# max32690 register map
Vendor: Maxim-Integrated; Series: ARMCM4; File version: 1.0
CPU: CM4 r2p1, little endian, MPU, FPU, 3 interrupt priority bits
Registers are 32-bit, read-write, reset 0x0 unless marked. A register's access mark holds for its fields unless they carry their own. Offsets are from the block's base; [hi:lo] are bit positions; {n}, {i} and the like mark numbered series; 'fields as' and 'values as' point back to an identical list.

## CAN0 — Controller Area Network Registers
Base 0x40064000
Same registers: CAN2 ?, CAN1 0x40065000
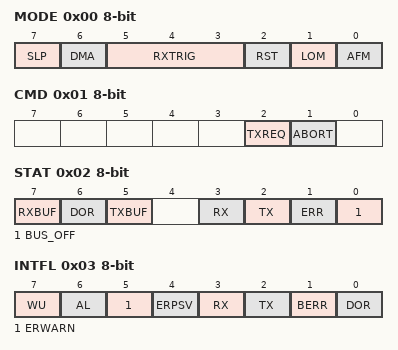
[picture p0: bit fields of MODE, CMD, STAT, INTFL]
0x00 MODE 8-bit
  [7] SLP — Sleep mode.
    1=Enter sleep mode; 0=Leave sleep mode
  [6] DMA — Enable DMA mode.
  [5:3] RXTRIG — Receive FIFO trigger in 32bit word.
    0=1W (1 word); 1=4W (4 word); 2=8W (8 word); 3=16W (16 word); 4=32W (32 word); 5=64W (64 word)
  [2] RST — Reset Mode.
  [1] LOM — Listen Only Mode.
  [0] AFM — Hardware acceptance filter scheme.
0x01 CMD 8-bit — Command Register.
  [2] TXREQ — Transmit Request.
  [1] ABORT — Abort Transmission
0x02 STAT 8-bit ro — Status Register.
  [7] RXBUF — Receive Buffer Status.
  [6] DOR — Data Overrun Status.
  [5] TXBUF — Transmit Buffer Status.
  [3] RX — Receive Status.
  [2] TX — Transmit Status.
  [1] ERR — Error Status.
  [0] BUS_OFF — Bus off Status.
0x03 INTFL 8-bit — Interrupt Status Register.
  [7] WU — Wake-up Interrupt.
  [6] AL — Arbitration Lost Interrupt.
  [5] ERWARN — Error Warning Interrupt.
  [4] ERPSV — Error Passive Interrupt.
  [3] RX — Receive Interrupt.
  [2] TX — Transmission Interrupt.
  [1] BERR — Bus Error Interrupt.
  [0] DOR — Data Overrun Interrupt.
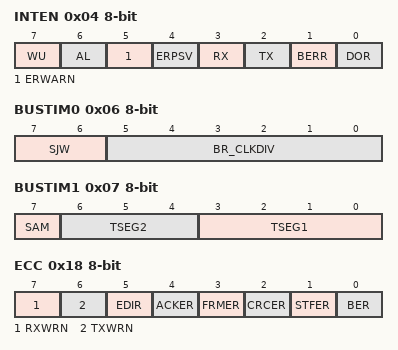
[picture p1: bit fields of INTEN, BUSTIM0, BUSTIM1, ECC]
0x04 INTEN 8-bit — Interrupt Enable Register.
  [7] WU — Wakeup interrupt.
  [6] AL — Arbitration Lost Interrupt.
  [5] ERWARN — Error Warning Interrupt.
  [4] ERPSV — Error Passive Interrupt.
  [3] RX — Receive Interrupt.
  [2] TX — Transmit Interrupt.
  [1] BERR — Bus Error Interrupt.
  [0] DOR — Data Overrun Interrupt.
0x05 RMC 8-bit — Receive Message Counter Register.
  [4:0] NUM_MSGS — Number of stored message frames.
0x06 BUSTIM0 8-bit — Bus Timing Register 0.
  [7:6] SJW — Synchronization Jump Width.
  [5:0] BR_CLKDIV — Baud Rate Prescaler.
0x07 BUSTIM1 8-bit — Bus Timing Register 1.
  [7] SAM — Number of bus level samples.
  [6:4] TSEG2 — Number of clock cycles per Time Segment 2
  [3:0] TSEG1 — Number of clock cycles per Time Segment 1
0x08 TXFIFO32 — Transmit FIFO Register.
  [31:0] DATA — Write to put into TX FIFO.
{0x8+2i} TXFIFO16[{i}] (i=0..1) 16-bit — Transmit FIFO Register.
  [15:0] DATA — Write to put into TX FIFO.
{0x8+i} TXFIFO8[{i}] (i=0..3) 8-bit — Transmit FIFO Register.
  [7:0] DATA — Write to put into TX FIFO.
0x0C RXFIFO32 ro — Receive FIFO Register.
  [31:0] DATA — Read from RX FIFO.
{0xC+2i} RXFIFO16[{i}] (i=0..1) 16-bit ro — Receive FIFO Register.
  [15:0] DATA — Read from RX FIFO.
{0xC+i} RXFIFO8[{i}] (i=0..3) 8-bit ro — Receive FIFO Register.
  [7:0] DATA — Read from RX FIFO.
0x10 ACR32 — Acceptance Code Register.
  [31:0] ACR — Acceptance Code.
{0x10+2i} ACR16[{i}] (i=0..1) 16-bit — Acceptance Code Register.
  [15:0] ACR — Acceptance Code.
{0x10+i} ACR8[{i}] (i=0..3) 8-bit — Acceptance Code Register.
  [7:0] ACR — Acceptance Code.
0x14 AMR32 — Acceptance Mask Register.
  [31:0] AMR — Acceptance Mask.
{0x14+2i} AMR16[{i}] (i=0..1) 16-bit — Acceptance Mask Register.
  [15:0] AMR — Acceptance Mask.
{0x14+i} AMR8[{i}] (i=0..3) 8-bit — Acceptance Mask Register.
  [7:0] AMR — Acceptance Mask.
0x18 ECC 8-bit ro — Error Code Capture Register.
  [7] RXWRN — Set when RXERR counter is greater than or equal to 96.
  [6] TXWRN — Set when TXERR counter is greater than or equal to 96.
  [5] EDIR — Direction of transfer while error occurred.
    0=TX (Transmission); 1=RX (Reception)
  [4] ACKER — ACK Error Occurred.
  [3] FRMER — Form Error Occurred.
  [2] CRCER — CRC Error Occurred.
  [1] STFER — Stuff Error Occurred.
  [0] BER — Bit Error Occurred.
0x19 RXERR 8-bit — Receive Error Counter.
0x1A TXERR 8-bit — Invalidate All Registers.
  [7:0] TXERR — Transmit Error Counter.
0x1B ALC 8-bit ro — Arbitration Lost Code Capture Register.
  [4:0] ALC — Arbitration Lost Capture.
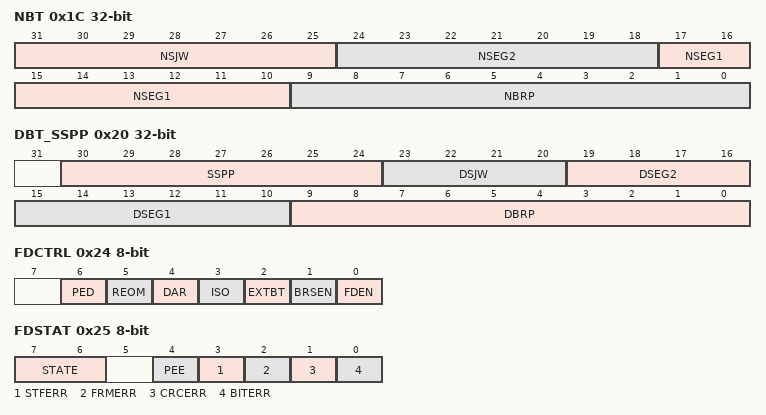
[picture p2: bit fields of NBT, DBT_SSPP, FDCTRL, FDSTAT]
0x1C NBT — Nominal Bit Timing Register.
  [31:25] NSJW — Synchronization Jump Width in Arbitration Phase.
  [24:18] NSEG2 — The time segment after the sample point in Abritration Phase.
  [17:10] NSEG1 — The time segment before the sample point in Abritration Phase.
  [9:0] NBRP — Baudrate Prescaler Used in Arbitration Phase.
0x20 DBT_SSPP — Data Bit Timing Register.
  [30:24] SSPP — Position of the secondary sample point.
  [23:20] DSJW — Synchronization Jump Width in Data Phase
  [19:16] DSEG2 — The time segment before the sample point in Data Phase.
  [15:10] DSEG1 — The time segment before the sample point in Data Phase.
  [9:0] DBRP — Baudrate Prescaler in Data Phase.
0x24 FDCTRL 8-bit — FD Control Register.
  [6] PED — Protocol Exception Disable.
  [5] REOM — Restricted Operation Mode.
  [4] DAR — Disable Auto Retransmission
    0=EN (Automatic retransmission enabled.); 1=DIS (Automatic retransmission disabled.)
  [3] ISO — ISO CAN FD Format Selection.
    0=BOSCH (Frame format according to Bosch CAN FD specification.); 1=ISO (Frame format according to ISO 11898 1, 2015.)
  [2] EXTBT — This bit configure the Bit Time prescaler in Arbitration phase.
    0=BT (Use contents of BT register to configure bit time in arbitration phase.); 1=NBT (Use contents of NBT register to configure bit time in arbitration phase.)
  [1] BRSEN — This bit indicates whether the bit rate is switched in Data phase.
    0=NOSW (Bit rate is not switced inside of CAN FD frame.); 1=SW (Bit rate is switched from nominal bit rate of the arbitration phase to alternate bit rate of data phase.)
  [0] FDEN — FD Frame format/ Extended data length. This bit indicates CAN FD frame format.
    1=fd (CAN FD Frame Format); 0=Classic CAN Frame Format
0x25 FDSTAT 8-bit ro — Invalidate All Registers.
  [7:6] STATE — Operation state.
    0=INT (Waiting for 11 recessive bit after reset or bus off); 1=IDLE (Waiting for Start of Frame.); 2=RX (Node operating as Receiver.); 3=TX (Node operating as Transmitter.)
  [4] PEE — Protocol Exception Event indicator. Indicates that core detects recessive state on res position and enter to Bus integration state.
  [3] STFERR — Stuff Error Indicator. This bit indicates stuff error occurred in Data phase in CAN FD frame with the BRS bit set
  [2] FRMERR — Form Error indicator. This bit indicates, that a fixed form bit field contains at least one illegal bit in Data phase of CAN FD frame with the BRS bit set
  [1] CRCERR — Cyclic Redundancy Check Error indicator. This indicates that calculated CRC is different from received in CAN FD frame
  [0] BITERR — Bit Error Indicator. When this bit is set the inconsistency occurs between the transmitted and the received bit in CAN FD frame.
0x26 DPERR 8-bit ro — Data Phase Error Counter Register.
  [7:0] DPERR — Data Phase Error Counter.
0x27 APERR 8-bit ro — Arbitration Phase Error Counter Register.
  [7:0] APERR — Arbitration Error Counter.
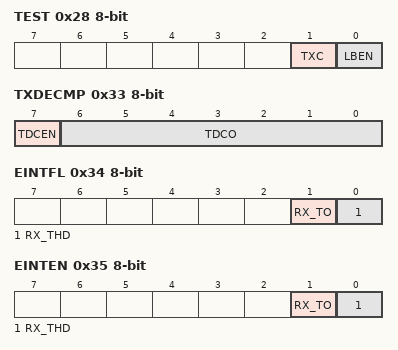
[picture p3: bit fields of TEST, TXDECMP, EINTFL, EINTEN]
0x28 TEST 8-bit — Invalidate All Registers.
  [1] TXC — Transmitted frame.
  [0] LBEN — Loopback mode.
0x29 WUPCLKDIV 8-bit — Wake-up timer prescaler.
  [7:0] WUPDIV
0x2A WUPFT 16-bit — Wake up Filter Time Register.
  [15:0] WUPFT — Wake-up pattern filter time.
0x2C WUPET — Wake-up Expire Time Register.
  [19:0] WUPET — Wake up patter expire time.
0x30 RXDCNT 16-bit — RX FIFO Data Counter Register.
  [15:0] RXDCNT — RX FIFO data counter.
0x32 TXSCNT 8-bit — TX FIFO Space Counter.
0x33 TXDECMP 8-bit — Invalidate All Registers.
  [7] TDCEN — Transceiver Delay Compensation Enable.
  [6:0] TDCO — Transceiver Delay Compensation Offset. This bit field contains the offset value added to the measured transceiver loop delay
0x34 EINTFL 8-bit — Extended Interrupt Flag Register.
  [1] RX_TO — RX FIFO Timeout Indicator. It is set when there is no write or read from/in to RX FIFO for the user defined time (RXFTO register) and there is at least 1 entry in RX FIFO during this time, this bit is clear by write 1
  [0] RX_THD — RX FIFO reach programmed trigger level, it is set when the RX FIFO reaches programmed trigger level (RT[2:0] in MR register). To clear the RXFT interrupt, write this bit 1
0x35 EINTEN 8-bit — Extended Interrupt Enable Register.
  fields as EINTFL
0x36 RXTO 16-bit — RX FIFO Timeout Register.
  [15:0] RX_TO — RX FIFO Timeout
